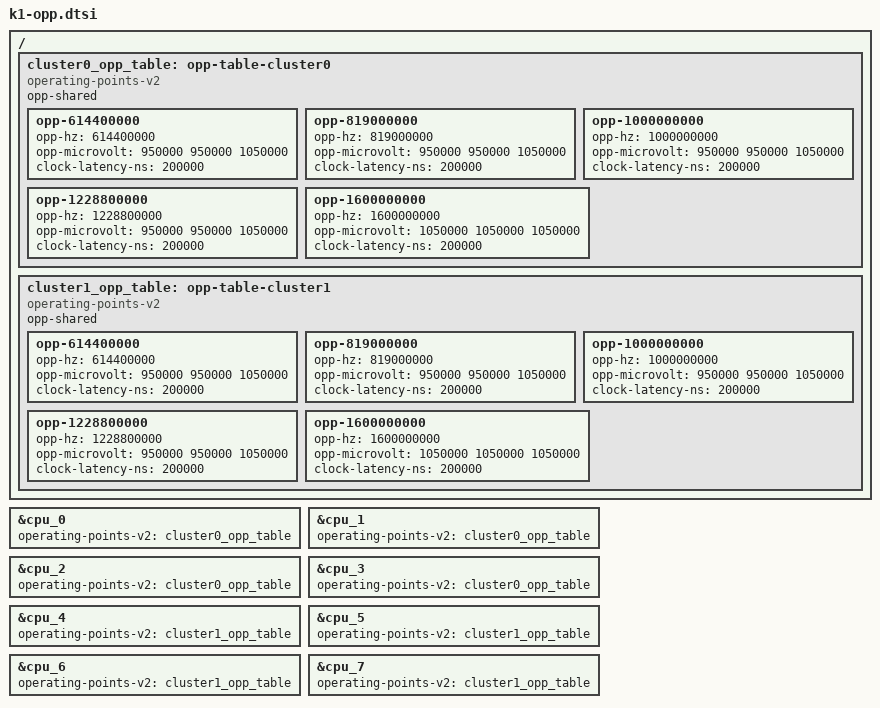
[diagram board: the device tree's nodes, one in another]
// SPDX-License-Identifier: (GPL-2.0+ OR MIT)

/ {
	cluster0_opp_table: opp-table-cluster0 {
		compatible = "operating-points-v2";
		opp-shared;

		opp-614400000 {
			opp-hz = /bits/ 64 <614400000>;
			opp-microvolt = <950000 950000 1050000>;
			clock-latency-ns = <200000>;
		};

		opp-819000000 {
			opp-hz = /bits/ 64 <819000000>;
			opp-microvolt = <950000 950000 1050000>;
			clock-latency-ns = <200000>;
		};

		opp-1000000000 {
			opp-hz = /bits/ 64 <1000000000>;
			opp-microvolt = <950000 950000 1050000>;
			clock-latency-ns = <200000>;
		};

		opp-1228800000 {
			opp-hz = /bits/ 64 <1228800000>;
			opp-microvolt = <950000 950000 1050000>;
			clock-latency-ns = <200000>;
		};

		opp-1600000000 {
			opp-hz = /bits/ 64 <1600000000>;
			opp-microvolt = <1050000 1050000 1050000>;
			clock-latency-ns = <200000>;
		};
	};

	cluster1_opp_table: opp-table-cluster1 {
		compatible = "operating-points-v2";
		opp-shared;

		opp-614400000 {
			opp-hz = /bits/ 64 <614400000>;
			opp-microvolt = <950000 950000 1050000>;
			clock-latency-ns = <200000>;
		};

		opp-819000000 {
			opp-hz = /bits/ 64 <819000000>;
			opp-microvolt = <950000 950000 1050000>;
			clock-latency-ns = <200000>;
		};

		opp-1000000000 {
			opp-hz = /bits/ 64 <1000000000>;
			opp-microvolt = <950000 950000 1050000>;
			clock-latency-ns = <200000>;
		};

		opp-1228800000 {
			opp-hz = /bits/ 64 <1228800000>;
			opp-microvolt = <950000 950000 1050000>;
			clock-latency-ns = <200000>;
		};

		opp-1600000000 {
			opp-hz = /bits/ 64 <1600000000>;
			opp-microvolt = <1050000 1050000 1050000>;
			clock-latency-ns = <200000>;
		};
	};
};

&cpu_0 {
	operating-points-v2 = <&cluster0_opp_table>;
};

&cpu_1 {
	operating-points-v2 = <&cluster0_opp_table>;
};

&cpu_2 {
	operating-points-v2 = <&cluster0_opp_table>;
};

&cpu_3 {
	operating-points-v2 = <&cluster0_opp_table>;
};

&cpu_4 {
	operating-points-v2 = <&cluster1_opp_table>;
};

&cpu_5 {
	operating-points-v2 = <&cluster1_opp_table>;
};

&cpu_6 {
	operating-points-v2 = <&cluster1_opp_table>;
};

&cpu_7 {
	operating-points-v2 = <&cluster1_opp_table>;
};
